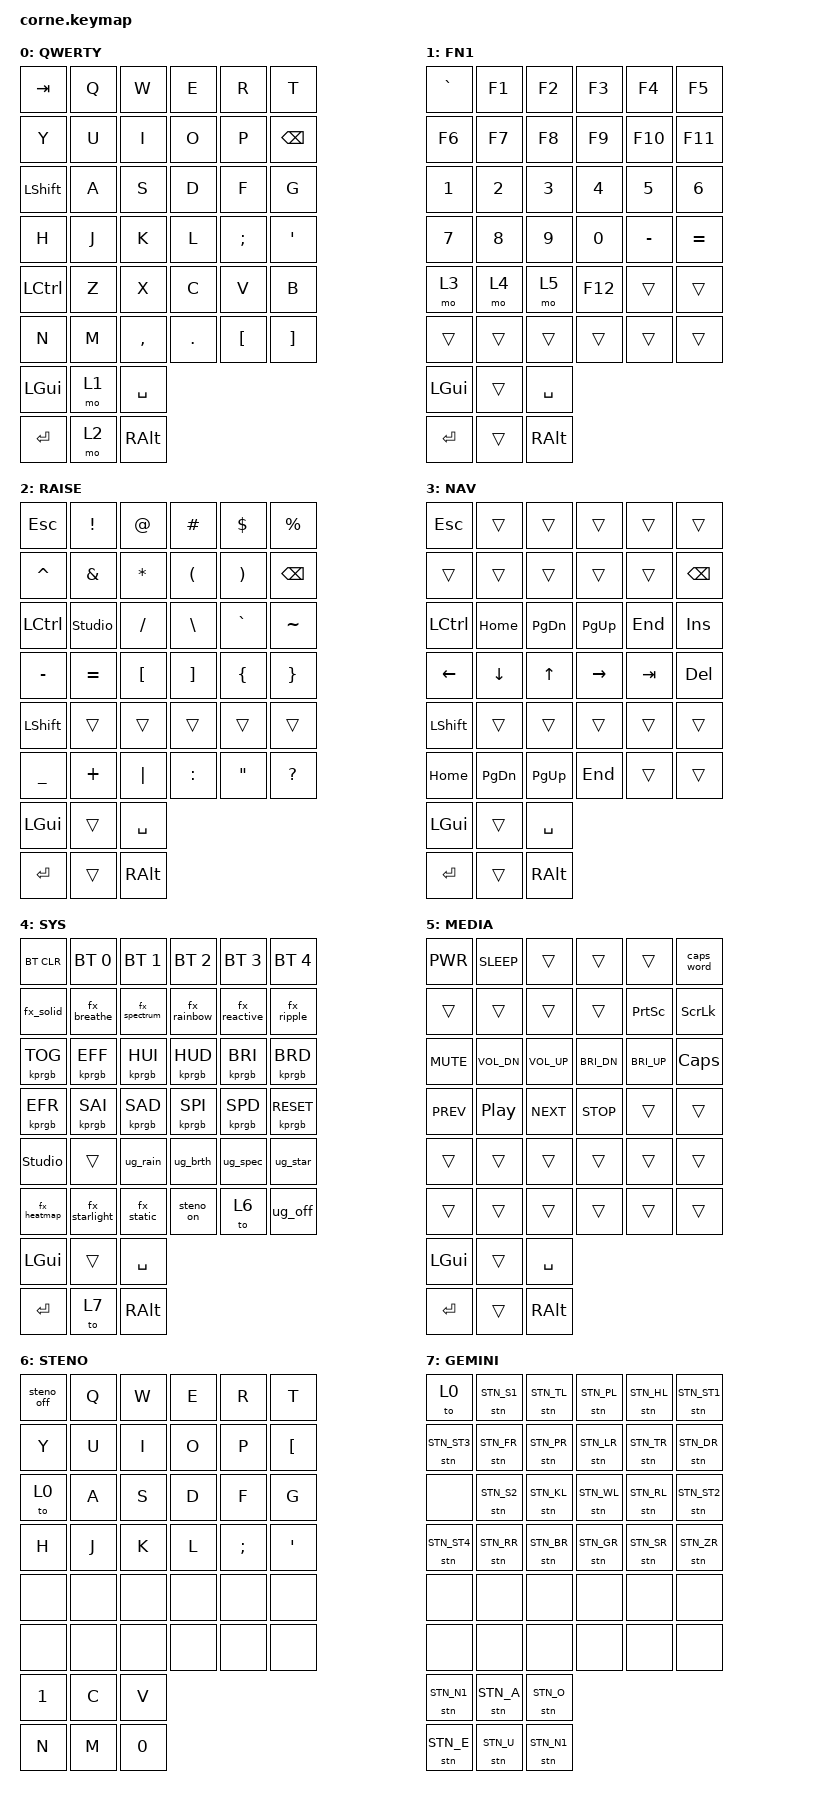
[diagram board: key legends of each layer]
#include <behaviors.dtsi>
#include <dt-bindings/zmk/keys.h>
#include <dt-bindings/zmk/bt.h>
#include <dt-bindings/zmk/rgb.h>
#include <dt-bindings/keypaw/rgb_matrix.h>
#include <dt-bindings/steno/gemini.h>

&caps_word {
    continue-list = <UNDERSCORE>;
};

&led_strip {
    chain-length = <27>;
};

/*
 * RGB por tecla (zmk-rgb-matrix)
 *
 * Os efeitos, as condicoes e os overlays abaixo precisam ser IDENTICOS nas
 * duas metades (e estao aqui, no keymap compartilhado, por isso): o efeito e o
 * overlay sao identificados pela posicao em que foram declarados.
 * O mapeamento dos LEDs de cada metade fica em corne_left.overlay e
 * corne_right.overlay. As cores de cada LED em cada camada ficam em
 * led_colors.dtsi (incluido no fim deste arquivo): o slot-colors dos mapas e
 * o mesmo nas duas metades, cada uma usa so os slots dos seus LEDs.
 *
 * Os mapas de cor (efeitos static com layer-id) podem ser editados e salvos
 * pelo ZMK Studio. O layer-id e o ID da camada: a ordem em que ela foi
 * declarada no keymap (0 = QWERTY, 1 = FN1, 2 = RAISE, 3 = NAV, 4 = SYS,
 * 5 = MEDIA, 6 = STENO, 7 = GEMINI). O ID nao muda se as camadas forem
 * reordenadas no ZMK Studio.
 */
/ {
    behaviors {
        kprgb: kprgb {
            compatible = "keypaw,behavior-rgb-matrix";
            #binding-cells = <2>;
            initial-effect = <0>;
            initial-brightness = <20>;
            max-brightness = <50>;
            idle-brightness = <10>;

            // 0 - cor unica (ajuste com RGB_HUI/HUD/SAI/SAD)
            fx_solid: fx_solid {
                compatible = "keypaw,rgb-matrix-solid";
                #binding-cells = <0>;
                color = <0xFF0000>;
            };

            // 1 - respirando
            fx_breathe: fx_breathe {
                compatible = "keypaw,rgb-matrix-breathe";
                #binding-cells = <0>;
                color = <0x0000FF>;
                duration = <3000>;
            };

            // 2 - todas as teclas ciclam pelo espectro juntas
            fx_spectrum: fx_spectrum {
                compatible = "keypaw,rgb-matrix-spectrum";
                #binding-cells = <0>;
                duration = <6000>;
            };

            // 3 - arco-iris varrendo da esquerda para a direita
            fx_rainbow: fx_rainbow {
                compatible = "keypaw,rgb-matrix-rainbow";
                #binding-cells = <0>;
                color = <0xFFFFFF>;
                duration = <4000>;
                basis = "x";
                direction = "out";
                palette = "rainbow";
            };

            // 4 - acende ao redor da tecla pressionada
            fx_reactive: fx_reactive {
                compatible = "keypaw,rgb-matrix-reactive";
                #binding-cells = <0>;
                color = <0x00FFFF>;
                spread = "disc";
                spread-radius = <250>;
            };

            // 5 - ondas a partir da tecla pressionada
            fx_ripple: fx_ripple {
                compatible = "keypaw,rgb-matrix-ripple";
                #binding-cells = <0>;
                color = <0x00FFFF>;
            };

            // 6 - mapa de calor das teclas mais usadas
            fx_heatmap: fx_heatmap {
                compatible = "keypaw,rgb-matrix-heatmap";
                #binding-cells = <0>;
            };

            // 7 - brilhos aleatorios suaves
            fx_starlight: fx_starlight {
                compatible = "keypaw,rgb-matrix-starlight";
                #binding-cells = <0>;
                color = <0xFFFFFF>;
                smooth;
            };

            // 8 - mapa de cores da camada base (QWERTY); as cores ficam em
            // led_colors.dtsi, no bloco &fx_static
            fx_static: fx_static {
                compatible = "keypaw,rgb-matrix-static";
                #binding-cells = <0>;
                layer-id = <0>;
            };
        };

        // Tecla de estenotipia do protocolo GeminiPR (camada GEMINI). O parametro e
        // o STN_* de dt-bindings/steno/gemini.h. Quando a ultima tecla do acorde e
        // solta, o acorde inteiro vai ao Plover por uma porta serial USB. O codigo
        // esta em src/behavior_steno_gemini.c e a porta, em corne_left.overlay.
        stn: stn {
            compatible = "zmk,behavior-steno-gemini";
            #binding-cells = <1>;
            display-name = "Steno";
        };
    };

    rgb_conditions: rgb_conditions {
        compatible = "keypaw,rgb-conditions";

        // Caps Lock do computador
        cond_caps: cond_caps {
            compatible = "keypaw,rgb-condition-caps-lock";
        };

        // Camadas. O numero e o ID da camada: a ordem em que ela foi declarada
        // no keymap (1 = FN1 ... 7 = GEMINI), que nao muda quando as camadas sao
        // reordenadas no ZMK Studio.
        cond_fn1: cond_fn1 {
            compatible = "keypaw,rgb-condition-layer";
            layer = <1>;
        };
        cond_raise: cond_raise {
            compatible = "keypaw,rgb-condition-layer";
            layer = <2>;
        };
        cond_nav: cond_nav {
            compatible = "keypaw,rgb-condition-layer";
            layer = <3>;
        };
        cond_sys: cond_sys {
            compatible = "keypaw,rgb-condition-layer";
            layer = <4>;
        };
        cond_media: cond_media {
            compatible = "keypaw,rgb-condition-layer";
            layer = <5>;
        };
        cond_steno: cond_steno {
            compatible = "keypaw,rgb-condition-layer";
            layer = <6>;
        };
        cond_gemini: cond_gemini {
            compatible = "keypaw,rgb-condition-layer";
            layer = <7>;
        };

        // Animacoes do underglow. Cada condicao e um interruptor (latch) que uma
        // tecla da camada SYS liga e desliga: &ug_rain, &ug_brth, &ug_spec,
        // &ug_star e &ug_off. O estado fica so na RAM: ao desligar o teclado todos
        // voltam a desligados. O nome do no de cada interruptor tem no maximo 8
        // caracteres (o enlace entre as metades guarda o nome em 9 bytes).
        cond_ugrain: cond_ugrain {
            compatible = "keypaw,rgb-condition-latch";
            ug_rain: ug_rain {
                compatible = "keypaw,behavior-rgb-overlay-toggle";
                #binding-cells = <0>;
            };
        };
        cond_ugbrth: cond_ugbrth {
            compatible = "keypaw,rgb-condition-latch";
            ug_brth: ug_brth {
                compatible = "keypaw,behavior-rgb-overlay-toggle";
                #binding-cells = <0>;
            };
        };
        cond_ugspec: cond_ugspec {
            compatible = "keypaw,rgb-condition-latch";
            ug_spec: ug_spec {
                compatible = "keypaw,behavior-rgb-overlay-toggle";
                #binding-cells = <0>;
            };
        };
        cond_ugstar: cond_ugstar {
            compatible = "keypaw,rgb-condition-latch";
            ug_star: ug_star {
                compatible = "keypaw,behavior-rgb-overlay-toggle";
                #binding-cells = <0>;
            };
        };
        cond_ugoff: cond_ugoff {
            compatible = "keypaw,rgb-condition-latch";
            ug_off: ug_off {
                compatible = "keypaw,behavior-rgb-overlay-toggle";
                #binding-cells = <0>;
            };
        };
    };

    // A ordem de declaracao e a ordem de pintura: o ultimo fica por cima.
    rgb_overlays: rgb_overlays {
        compatible = "keypaw,rgb-overlays";

        // Animacoes do underglow (ligadas pelas teclas &ug_* da camada SYS). Cada
        // uma pinta so os 6 LEDs de underglow de cada metade (LEDs 0 a 5 da fita)
        // com um efeito proprio, e as teclas seguem o efeito principal. Vem antes
        // dos mapas de camada, que cobrem a metade inteira: enquanto uma camada de
        // FN1 a GEMINI esta ativa o underglow mostra a cor dela. Com mais de uma
        // ligada vale a de baixo da lista, e &ug_off (underglow apagado) vence todas.
        ov_ugrain: ov_ugrain {
            compatible = "keypaw,rgb-overlay";
            condition = <&cond_ugrain>;
            leds = <0 1 2 3 4 5>;
            fx_ov_ugrain {
                compatible = "keypaw,rgb-matrix-rainbow";
                #binding-cells = <0>;
                color = <0xFFFFFF>;
                duration = <4000>;
                basis = "x";
                direction = "out";
                palette = "rainbow";
            };
        };
        ov_ugbrth: ov_ugbrth {
            compatible = "keypaw,rgb-overlay";
            condition = <&cond_ugbrth>;
            leds = <0 1 2 3 4 5>;
            fx_ov_ugbrth {
                compatible = "keypaw,rgb-matrix-breathe";
                #binding-cells = <0>;
                color = <0x00FFFF>;
                duration = <4000>;
            };
        };
        ov_ugspec: ov_ugspec {
            compatible = "keypaw,rgb-overlay";
            condition = <&cond_ugspec>;
            leds = <0 1 2 3 4 5>;
            fx_ov_ugspec {
                compatible = "keypaw,rgb-matrix-spectrum";
                #binding-cells = <0>;
                duration = <6000>;
            };
        };
        ov_ugstar: ov_ugstar {
            compatible = "keypaw,rgb-overlay";
            condition = <&cond_ugstar>;
            leds = <0 1 2 3 4 5>;
            fx_ov_ugstar {
                compatible = "keypaw,rgb-matrix-starlight";
                #binding-cells = <0>;
                color = <0xFFFFFF>;
                smooth;
            };
        };
        ov_ugoff: ov_ugoff {
            compatible = "keypaw,rgb-overlay";
            condition = <&cond_ugoff>;
            leds = <0 1 2 3 4 5>;
            fx_ov_ugoff {
                compatible = "keypaw,rgb-matrix-solid";
                #binding-cells = <0>;
                color = <0x000000>;
            };
        };

        // Mapa de cores de cada camada (FN1 a GEMINI). Enquanto a camada esta
        // ativa, o overlay cobre todos os LEDs da metade (teclas e underglow)
        // com as cores de led_colors.dtsi e o efeito principal fica pausado por
        // baixo. Segurando FN1 + SYS ao mesmo tempo, o mapa de SYS fica por cima.
        ov_fn1: ov_fn1 {
            compatible = "keypaw,rgb-overlay";
            condition = <&cond_fn1>;
            all-leds;
            map_fn1: fx_ov_fn1 {
                compatible = "keypaw,rgb-matrix-static";
                #binding-cells = <0>;
                layer-id = <1>;
            };
        };
        ov_raise: ov_raise {
            compatible = "keypaw,rgb-overlay";
            condition = <&cond_raise>;
            all-leds;
            map_raise: fx_ov_raise {
                compatible = "keypaw,rgb-matrix-static";
                #binding-cells = <0>;
                layer-id = <2>;
            };
        };
        ov_nav: ov_nav {
            compatible = "keypaw,rgb-overlay";
            condition = <&cond_nav>;
            all-leds;
            map_nav: fx_ov_nav {
                compatible = "keypaw,rgb-matrix-static";
                #binding-cells = <0>;
                layer-id = <3>;
            };
        };
        ov_sys: ov_sys {
            compatible = "keypaw,rgb-overlay";
            condition = <&cond_sys>;
            all-leds;
            map_sys: fx_ov_sys {
                compatible = "keypaw,rgb-matrix-static";
                #binding-cells = <0>;
                layer-id = <4>;
            };
        };
        ov_media: ov_media {
            compatible = "keypaw,rgb-overlay";
            condition = <&cond_media>;
            all-leds;
            map_media: fx_ov_media {
                compatible = "keypaw,rgb-matrix-static";
                #binding-cells = <0>;
                layer-id = <5>;
            };
        };
        ov_steno: ov_steno {
            compatible = "keypaw,rgb-overlay";
            condition = <&cond_steno>;
            all-leds;
            map_steno: fx_ov_steno {
                compatible = "keypaw,rgb-matrix-static";
                #binding-cells = <0>;
                layer-id = <6>;
            };
        };
        ov_gemini: ov_gemini {
            compatible = "keypaw,rgb-overlay";
            condition = <&cond_gemini>;
            all-leds;
            map_gemini: fx_ov_gemini {
                compatible = "keypaw,rgb-matrix-static";
                #binding-cells = <0>;
                layer-id = <7>;
            };
        };

        // Caps Lock: acende a coluna externa da metade esquerda (TAB e as duas
        // teclas abaixo) em branco.
        ov_caps: ov_caps {
            compatible = "keypaw,rgb-overlay";
            condition = <&cond_caps>;
            keys = <0 12 24>;
            fx_ov_caps {
                compatible = "keypaw,rgb-matrix-solid";
                #binding-cells = <0>;
                color = <0xFFFFFF>;
            };
        };
    };
};

/*
 * Modo de estenotipia (Plover)
 *
 * A camada STENO (ID 6) faz o teclado mandar as teclas de um teclado de
 * estenotipia no mapa padrao "Keyboard" do Plover (cada tecla manda a letra que
 * o Plover le como uma tecla de steno). O Plover precisa estar aberto no
 * computador, com a maquina "Keyboard" e os dicionarios padrao (o commands.json
 * traz os acordes de ligar e desligar).
 *
 * Os dois macros abaixo trocam de camada e mandam ao Plover o acorde que liga
 * ou desliga a saida de steno, para o computador acompanhar o teclado:
 *   steno_on  : vai para a camada STENO e manda PHRO*PB ({PLOVER:RESUME})
 *   steno_off : volta para a camada QWERTY e manda PHRO*F ({PLOVER:SUSPEND})
 * Para trocar so a camada, sem falar com o Plover, use &to 6 e &to 0.
 *
 * Os acordes sao os do commands.json do Plover, escritos nas teclas do mapa
 * padrao: P- H- R- O- = E R F V, * = T, -F = U, -P = I, -B = K. O de ligar tem 7
 * teclas ao mesmo tempo, por isso o NKRO (CONFIG_ZMK_HID_REPORT_TYPE_NKRO em
 * corne.conf) e obrigatorio.
 */
/ {
    macros {
        steno_on: steno_on {
            compatible = "zmk,behavior-macro";
            #binding-cells = <0>;
            display-name = "Steno On";
            wait-ms = <20>;
            tap-ms = <20>;
            bindings = <
                &to 6
                &macro_press
                &kp E &kp R &kp F &kp V &kp T &kp I &kp K
                &macro_release
                &kp E &kp R &kp F &kp V &kp T &kp I &kp K
            >;
        };

        steno_off: steno_off {
            compatible = "zmk,behavior-macro";
            #binding-cells = <0>;
            display-name = "Steno Off";
            wait-ms = <20>;
            tap-ms = <20>;
            bindings = <
                &to 0
                &macro_press
                &kp E &kp R &kp F &kp V &kp T &kp U
                &macro_release
                &kp E &kp R &kp F &kp V &kp T &kp U
            >;
        };
    };
};

/ {
    keymap {
        compatible = "zmk,keymap";

        // 0 — base (padrão ZMK Studio)
        default_layer {
            display-name = "QWERTY";

            bindings = <
                &kp TAB   &kp Q     &kp W     &kp E     &kp R     &kp T
                &kp Y     &kp U     &kp I     &kp O     &kp P     &kp BSPC

                &kp LSHFT &kp A     &kp S     &kp D     &kp F     &kp G
                &kp H     &kp J     &kp K     &kp L     &kp SEMI  &kp SQT

                &kp LCTRL &kp Z     &kp X     &kp C     &kp V     &kp B
                &kp N     &kp M     &kp COMMA &kp DOT   &kp LBKT  &kp RBKT

                &kp LGUI  &mo 1     &kp SPACE
                &kp RET   &mo 2     &kp RALT
            >;
        };

        // 1 — números e F-keys (antiga LOWER)
        fn1_layer {
            display-name = "FN1";

            bindings = <
                &kp GRAVE &kp F1    &kp F2    &kp F3    &kp F4    &kp F5
                &kp F6    &kp F7    &kp F8    &kp F9    &kp F10   &kp F11

                &kp N1    &kp N2    &kp N3    &kp N4    &kp N5    &kp N6
                &kp N7    &kp N8    &kp N9    &kp N0    &kp MINUS &kp EQUAL

                &mo 3     &mo 4     &mo 5     &kp F12   &trans    &trans
                &trans    &trans    &trans    &trans    &trans    &trans

                &kp LGUI  &trans    &kp SPACE
                &kp RET   &trans    &kp RALT
            >;
        };

        // 2 — símbolos
        raise_layer {
            display-name = "RAISE";

            bindings = <
                &kp ESC   &kp EXCL  &kp AT    &kp HASH  &kp DLLR  &kp PRCNT
                &kp CARET &kp AMPS  &kp ASTRK &kp LPAR  &kp RPAR  &kp BSPC

                &kp LCTRL &studio_unlock &kp FSLH &kp BSLH &kp GRAVE &kp TILDE
                &kp MINUS &kp EQUAL &kp LBKT  &kp RBKT  &kp LBRC  &kp RBRC

                &kp LSHFT &trans    &trans    &trans    &trans    &trans
                &kp UNDER &kp PLUS  &kp PIPE  &kp COLON &kp DQT   &kp QMARK

                &kp LGUI  &trans    &kp SPACE
                &kp RET   &trans    &kp RALT
            >;
        };

        // 3 — navegação (setas da antiga LOWER + extras)
        nav_layer {
            display-name = "NAV";

            bindings = <
                &kp ESC   &trans    &trans    &trans    &trans    &trans
                &trans    &trans    &trans    &trans    &trans    &kp BSPC

                &kp LCTRL &kp HOME  &kp PG_DN &kp PG_UP &kp END   &kp INS
                &kp LEFT  &kp DOWN  &kp UP    &kp RIGHT &kp TAB   &kp DEL

                &kp LSHFT &trans    &trans    &trans    &trans    &trans
                &kp HOME  &kp PG_DN &kp PG_UP &kp END   &trans    &trans

                &kp LGUI  &trans    &kp SPACE
                &kp RET   &trans    &kp RALT
            >;
        };

        // 4 — Bluetooth + RGB
        //   esquerda: BT na 1a fileira; liga/desliga, efeito, cor e brilho na 2a;
        //             na 3a, a liberacao do Studio e as animacoes do underglow
        //             (&ug_rain, &ug_brth, &ug_spec e &ug_star)
        //   direita : efeitos diretos na 1a fileira; EFR/saturacao/velocidade/
        //             reset na 2a; mais tres efeitos na 3a e, depois deles, os
        //             comandos do modo STENO (&steno_on e &to 6) e o &ug_off,
        //             que apaga o underglow
        //   polegares: &to 7 (direita, no meio) liga a camada GEMINI
        sys_layer {
            display-name = "SYS";

            bindings = <
                &bt BT_CLR      &bt BT_SEL 0    &bt BT_SEL 1    &bt BT_SEL 2    &bt BT_SEL 3    &bt BT_SEL 4
                &fx_solid       &fx_breathe     &fx_spectrum    &fx_rainbow     &fx_reactive    &fx_ripple

                &kprgb RGB_TOG  &kprgb RGB_EFF  &kprgb RGB_HUI  &kprgb RGB_HUD  &kprgb RGB_BRI  &kprgb RGB_BRD
                &kprgb RGB_EFR  &kprgb RGB_SAI  &kprgb RGB_SAD  &kprgb RGB_SPI  &kprgb RGB_SPD  &kprgb RGB_RESET

                &studio_unlock  &trans          &ug_rain        &ug_brth        &ug_spec        &ug_star
                &fx_heatmap     &fx_starlight   &fx_static      &steno_on       &to 6           &ug_off

                &kp LGUI  &trans    &kp SPACE
                &kp RET   &to 7     &kp RALT
            >;
        };

        // 5 — mídia e atalhos úteis
        media_layer {
            display-name = "MEDIA";

            bindings = <
                &kp C_PWR  &kp C_SLEEP &trans    &trans    &trans    &caps_word
                &trans     &trans      &trans    &trans    &kp PSCRN &kp SLCK

                &kp C_MUTE &kp C_VOL_DN &kp C_VOL_UP &kp C_BRI_DN &kp C_BRI_UP &kp CAPS
                &kp C_PREV &kp C_PP     &kp C_NEXT   &kp C_STOP   &trans       &trans

                &trans     &trans       &trans       &trans       &trans       &trans
                &trans     &trans       &trans       &trans       &trans       &trans

                &kp LGUI  &trans    &kp SPACE
                &kp RET   &trans    &kp RALT
            >;
        };

        // 6 — estenotipia (Plover, mapa padrão "Keyboard")
        //   Cada tecla manda a letra que o Plover lê como uma tecla de steno:
        //   esquerda: S T P H * na 1a fileira, S K W R * na 2a, A O nos polegares
        //   direita : * F P L T D na 1a fileira, * R B G S Z na 2a, E U nos polegares
        //   barra de números nos polegares externos; a 3a fileira fica sem uso.
        //   Saída: &steno_off (camada QWERTY + desliga o Plover) na 1a tecla da
        //   esquerda e &to 0 (só a camada) logo abaixo.
        steno_layer {
            display-name = "STENO";

            bindings = <
                &steno_off &kp Q    &kp W    &kp E    &kp R    &kp T
                &kp Y      &kp U    &kp I    &kp O    &kp P    &kp LBKT

                &to 0      &kp A    &kp S    &kp D    &kp F    &kp G
                &kp H      &kp J    &kp K    &kp L    &kp SEMI &kp SQT

                &none      &none    &none    &none    &none    &none
                &none      &none    &none    &none    &none    &none

                &kp N1     &kp C    &kp V
                &kp N      &kp M    &kp N0
            >;
        };

        // 7 — estenotipia GeminiPR (Plover, máquina "Gemini PR", só por USB)
        //   Cada tecla &stn soma uma chave ao acorde; quando a última tecla do
        //   acorde é solta, o teclado manda o acorde inteiro ao Plover por uma
        //   porta serial USB (nada é digitado). Mesmo arranjo da camada STENO:
        //   esquerda: S T P H *1 na 1a fileira, S K W R *2 na 2a, # A O nos polegares
        //   direita : *3 F P L T D na 1a fileira, *4 R B G S Z na 2a, E U # nos polegares
        //   a 3a fileira fica sem uso.
        //   Saída: &to 0 na 1a tecla da esquerda (volta à camada QWERTY).
        gemini_layer {
            display-name = "GEMINI";

            bindings = <
                &to 0        &stn STN_S1  &stn STN_TL  &stn STN_PL  &stn STN_HL  &stn STN_ST1
                &stn STN_ST3 &stn STN_FR  &stn STN_PR  &stn STN_LR  &stn STN_TR  &stn STN_DR

                &none        &stn STN_S2  &stn STN_KL  &stn STN_WL  &stn STN_RL  &stn STN_ST2
                &stn STN_ST4 &stn STN_RR  &stn STN_BR  &stn STN_GR  &stn STN_SR  &stn STN_ZR

                &none        &none        &none        &none        &none        &none
                &none        &none        &none        &none        &none        &none

                &stn STN_N1  &stn STN_A   &stn STN_O
                &stn STN_E   &stn STN_U   &stn STN_N1
            >;
        };
    };
};

// Cores de cada LED em cada camada: preenche o led-colors dos mapas acima.
#include "led_colors.dtsi"
